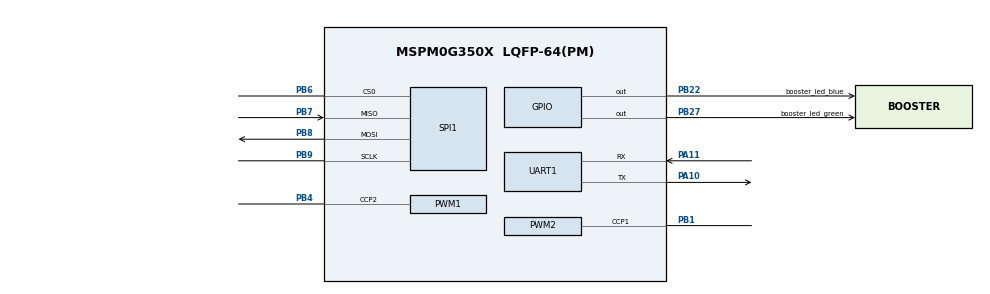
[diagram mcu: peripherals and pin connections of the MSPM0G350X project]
/**
 * @cliArgs --device "MSPM0G350X" --part "Default" --package "LQFP-64(PM)" --product "mspm0_sdk@2.08.00.03"
 * @versions {"tool":"1.26.0+4407"}
 */

/**
 * Import the modules used in this configuration.
 */
const ADC12  = scripting.addModule("/ti/driverlib/ADC12", {}, false);
const ADC121 = ADC12.addInstance();
const GPIO   = scripting.addModule("/ti/driverlib/GPIO", {}, false);
const GPIO1  = GPIO.addInstance();
const GPIO2  = GPIO.addInstance();
const PWM    = scripting.addModule("/ti/driverlib/PWM", {}, false);
const PWM1   = PWM.addInstance();
const PWM2   = PWM.addInstance();
const SPI    = scripting.addModule("/ti/driverlib/SPI", {}, false);
const SPI1   = SPI.addInstance();
const SYSCTL = scripting.addModule("/ti/driverlib/SYSCTL");
const UART   = scripting.addModule("/ti/driverlib/UART", {}, false);
const UART1  = UART.addInstance();

/**
 * Write custom configuration values to the imported modules.
 */
ADC121.$name               = "ADC12_0";
ADC121.sampClkSrc          = "DL_ADC12_CLOCK_ULPCLK";
ADC121.sampClkDiv          = "DL_ADC12_CLOCK_DIVIDE_4";
ADC121.adcMem0chansel      = "DL_ADC12_INPUT_CHAN_2";
ADC121.repeatMode          = true;
ADC121.sampleTime0         = "125 us";
ADC121.enabledInterrupts   = ["DL_ADC12_INTERRUPT_MEM0_RESULT_LOADED"];
ADC121.peripheral.$assign  = "ADC0";
ADC121.adcPin2Config.$name = "ti_driverlib_gpio_GPIOPinGeneric8";

const Board = scripting.addModule("/ti/driverlib/Board", {}, false);

GPIO1.$name                               = "GPIO_LED";
GPIO1.associatedPins.create(3);
GPIO1.associatedPins[0].$name             = "booster_led_blue";
GPIO1.associatedPins[0].launchPadShortcut = "LED2BlueEn";
GPIO1.associatedPins[0].pin.$assign       = "PB22";
GPIO1.associatedPins[1].$name             = "booster_led_green";
GPIO1.associatedPins[1].launchPadShortcut = "LED2GreenEn";
GPIO1.associatedPins[1].pin.$assign       = "PB27";
GPIO1.associatedPins[2].$name             = "booster_led_red";
GPIO1.associatedPins[2].launchPadShortcut = "LED2RedEn";

GPIO2.$name                          = "EXTRA";
GPIO2.associatedPins.create(3);
GPIO2.associatedPins[0].$name        = "RST";
GPIO2.associatedPins[0].assignedPort = "PORTA";
GPIO2.associatedPins[0].assignedPin  = "28";
GPIO2.associatedPins[1].$name        = "DC";
GPIO2.associatedPins[1].assignedPin  = "13";
GPIO2.associatedPins[1].assignedPort = "PORTA";
GPIO2.associatedPins[2].$name        = "CS";

PWM1.$name                      = "PWM_0";
PWM1.ccIndex                    = [2];
PWM1.clockSource                = "LFCLK";
PWM1.timerCount                 = 40;
PWM1.peripheral.ccp2Pin.$assign = "PB4";
PWM1.PWM_CHANNEL_2.$name        = "ti_driverlib_pwm_PWMTimerCC0";
PWM1.PWM_CHANNEL_2.dutyCycle    = 100;
PWM1.ccp2PinConfig.$name        = "ti_driverlib_gpio_GPIOPinGeneric5";

PWM2.$name                      = "PWM_1";
PWM2.ccIndex                    = [1];
PWM2.clockSource                = "LFCLK";
PWM2.timerCount                 = 200;
PWM2.clockDivider               = 4;
PWM2.ccp1PinConfig.$name        = "ti_driverlib_gpio_GPIOPinGeneric1";
PWM2.peripheral.ccp1Pin.$assign = "PB1";
PWM2.PWM_CHANNEL_1.$name        = "ti_driverlib_pwm_PWMTimerCC1";
PWM2.PWM_CHANNEL_1.dutyCycle    = 50;

SPI1.$name                      = "SPI_0";
SPI1.peripheral.$assign         = "SPI1";
SPI1.peripheral.sclkPin.$assign = "PB9";
SPI1.peripheral.mosiPin.$assign = "PB8";
SPI1.peripheral.misoPin.$assign = "PB7";
SPI1.peripheral.cs0Pin.$assign  = "PB6";
SPI1.sclkPinConfig.$name        = "ti_driverlib_gpio_GPIOPinGeneric0";
SPI1.mosiPinConfig.$name        = "ti_driverlib_gpio_GPIOPinGeneric2";
SPI1.misoPinConfig.$name        = "ti_driverlib_gpio_GPIOPinGeneric6";
SPI1.cs0PinConfig.$name         = "ti_driverlib_gpio_GPIOPinGeneric7";

SYSCTL.forceDefaultClkConfig = true;
SYSCTL.clockTreeEn           = true;

UART1.$name                    = "UART_0";
UART1.targetBaudRate           = 115200;
UART1.uartClkDiv               = "4";
UART1.peripheral.rxPin.$assign = "PA11";
UART1.peripheral.txPin.$assign = "PA10";
UART1.txPinConfig.$name        = "ti_driverlib_gpio_GPIOPinGeneric3";
UART1.rxPinConfig.$name        = "ti_driverlib_gpio_GPIOPinGeneric4";

/**
 * Pinmux solution for unlocked pins/peripherals. This ensures that minor changes to the automatic solver in a future
 * version of the tool will not impact the pinmux you originally saw.  These lines can be completely deleted in order to
 * re-solve from scratch.
 */
ADC121.peripheral.adcPin2.$suggestSolution   = "PA25";
Board.peripheral.$suggestSolution            = "DEBUGSS";
Board.peripheral.swclkPin.$suggestSolution   = "PA20";
Board.peripheral.swdioPin.$suggestSolution   = "PA19";
GPIO1.associatedPins[2].pin.$suggestSolution = "PB26";
GPIO2.associatedPins[0].pin.$suggestSolution = "PA28";
GPIO2.associatedPins[1].pin.$suggestSolution = "PA13";
GPIO2.associatedPins[2].pin.$suggestSolution = "PB13";
PWM1.peripheral.$suggestSolution             = "TIMA0";
PWM2.peripheral.$suggestSolution             = "TIMA1";
UART1.peripheral.$suggestSolution            = "UART0";
